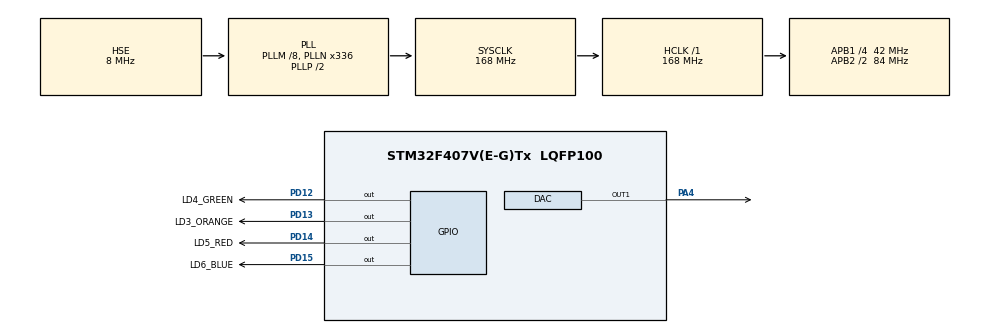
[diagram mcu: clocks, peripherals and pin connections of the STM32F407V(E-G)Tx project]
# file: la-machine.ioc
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DAC.DAC_Trigger=DAC_TRIGGER_T6_TRGO
Dma.DAC1.0.Direction=DMA_MEMORY_TO_PERIPH
Dma.DAC1.0.FIFOMode=DMA_FIFOMODE_DISABLE
Dma.DAC1.0.Instance=DMA1_Stream5
Dma.DAC1.0.MemDataAlignment=DMA_MDATAALIGN_HALFWORD
Dma.DAC1.0.MemInc=DMA_MINC_ENABLE
Dma.DAC1.0.Mode=DMA_CIRCULAR
Dma.DAC1.0.PeriphDataAlignment=DMA_PDATAALIGN_HALFWORD
Dma.DAC1.0.PeriphInc=DMA_PINC_DISABLE
Dma.DAC1.0.Priority=DMA_PRIORITY_LOW
Dma.Request0=DAC1
Mcu.Family=STM32F4
Mcu.Name=STM32F407V(E-G)Tx
Mcu.Package=LQFP100
NVIC.DMA1_Stream5_IRQn=true\:0\:0\:false\:false\:true\:false\:true\:true
NVIC.PriorityGroup=NVIC_PRIORITYGROUP_4
PA4.Signal=COMP_DAC1_group
PD12.GPIO_Label=LD4_GREEN
PD12.Signal=GPIO_Output
PD13.GPIO_Label=LD3_ORANGE
PD13.Signal=GPIO_Output
PD14.GPIO_Label=LD5_RED
PD14.Signal=GPIO_Output
PD15.GPIO_Label=LD6_BLUE
PD15.Signal=GPIO_Output
PH0-OSC_IN.Mode=HSE-External-Oscillator
PH0-OSC_IN.Signal=RCC_OSC_IN
PH1-OSC_OUT.Mode=HSE-External-Oscillator
PH1-OSC_OUT.Signal=RCC_OSC_OUT
ProjectManager.HeapSize=0x200
ProjectManager.StackSize=0x400
ProjectManager.TargetToolchain=Makefile
RCC.48MHZClocksFreq_Value=84000000
RCC.AHBFreq_Value=168000000
RCC.APB1CLKDivider=RCC_HCLK_DIV4
RCC.APB1Freq_Value=42000000
RCC.APB1TimFreq_Value=84000000
RCC.APB2CLKDivider=RCC_HCLK_DIV2
RCC.APB2Freq_Value=84000000
RCC.APB2TimFreq_Value=168000000
RCC.CortexFreq_Value=168000000
RCC.HCLKFreq_Value=168000000
RCC.HSE_VALUE=8000000
RCC.HSI_VALUE=16000000
RCC.LSE_VALUE=32768
RCC.PLLM=8
RCC.PLLN=336
RCC.PLLSourceVirtual=RCC_PLLSOURCE_HSE
RCC.SYSCLKFreq_VALUE=168000000
RCC.SYSCLKSource=RCC_SYSCLKSOURCE_PLLCLK
RCC.VCOOutputFreq_Value=336000000
SH.COMP_DAC1_group.0=DAC_OUT1,DAC_OUT1
TIM6.Period=1749
TIM6.TIM_MasterOutputTrigger=TIM_TRGO_UPDATE
VP_TIM6_VS_ClockSourceINT.Mode=Enable_Timer
board=custom

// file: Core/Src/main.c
/* USER CODE BEGIN Header */
/**
 ******************************************************************************
 * @file           : main.c
 * @brief          : Main program body
 ******************************************************************************
 * @attention
 *
 * Copyright (c) 2026 STMicroelectronics.
 * All rights reserved.
 *
 * This software is licensed under terms that can be found in the LICENSE file
 * in the root directory of this software component.
 * If no LICENSE file comes with this software, it is provided AS-IS.
 *
 ******************************************************************************
 */
/* USER CODE END Header */
#include "main.h"

/* USER CODE BEGIN Includes */

#include <math.h>

/* USER CODE END Includes */

DAC_HandleTypeDef hdac;
DMA_HandleTypeDef hdma_dac1;

TIM_HandleTypeDef htim6;

/* USER CODE BEGIN PV */
#define WAVETABLE_SIZE 512
float k_sine_wt[WAVETABLE_SIZE];

/* USER CODE END PV */

void SystemClock_Config(void);
static void MX_GPIO_Init(void);
static void MX_DMA_Init(void);
static void MX_DAC_Init(void);
static void MX_TIM6_Init(void);

/* USER CODE BEGIN 0 */

static void init_wavetables(void)
{
    // i might codegen this later
    for (int i = 0; i < WAVETABLE_SIZE; i++) {
        const float phase = (2.0f * 3.14159265f * i) / WAVETABLE_SIZE;
        k_sine_wt[i] = sinf(phase);
    }
}

/* USER CODE END 0 */

int main(void)
{
    /* USER CODE BEGIN 1 */
    init_wavetables();

    /* USER CODE END 1 */

    /* MCU
     * Configuration--------------------------------------------------------*/

    /* Reset of all peripherals, Initializes the Flash interface and the
     * Systick. */
    HAL_Init();

    /* Configure the system clock */
    SystemClock_Config();

    /* Initialize all configured peripherals */
    MX_GPIO_Init();
    MX_DMA_Init();
    MX_DAC_Init();
    MX_TIM6_Init();

    /* Infinite loop */
    while (1) {

    }
}

void SystemClock_Config(void)
{
    RCC_OscInitTypeDef RCC_OscInitStruct = {0};
    RCC_ClkInitTypeDef RCC_ClkInitStruct = {0};

    /** Configure the main internal regulator output voltage
     */
    __HAL_RCC_PWR_CLK_ENABLE();
    __HAL_PWR_VOLTAGESCALING_CONFIG(PWR_REGULATOR_VOLTAGE_SCALE1);

    /** Initializes the RCC Oscillators according to the specified parameters
     * in the RCC_OscInitTypeDef structure.
     */
    RCC_OscInitStruct.OscillatorType = RCC_OSCILLATORTYPE_HSE;
    RCC_OscInitStruct.HSEState = RCC_HSE_ON;
    RCC_OscInitStruct.PLL.PLLState = RCC_PLL_ON;
    RCC_OscInitStruct.PLL.PLLSource = RCC_PLLSOURCE_HSE;
    RCC_OscInitStruct.PLL.PLLM = 8;
    RCC_OscInitStruct.PLL.PLLN = 336;
    RCC_OscInitStruct.PLL.PLLP = RCC_PLLP_DIV2;
    RCC_OscInitStruct.PLL.PLLQ = 4;
    if (HAL_RCC_OscConfig(&RCC_OscInitStruct) != HAL_OK) {
        Error_Handler();
    }

    /** Initializes the CPU, AHB and APB buses clocks
     */
    RCC_ClkInitStruct.ClockType = RCC_CLOCKTYPE_HCLK | RCC_CLOCKTYPE_SYSCLK |
                                  RCC_CLOCKTYPE_PCLK1 | RCC_CLOCKTYPE_PCLK2;
    RCC_ClkInitStruct.SYSCLKSource = RCC_SYSCLKSOURCE_PLLCLK;
    RCC_ClkInitStruct.AHBCLKDivider = RCC_SYSCLK_DIV1;
    RCC_ClkInitStruct.APB1CLKDivider = RCC_HCLK_DIV4;
    RCC_ClkInitStruct.APB2CLKDivider = RCC_HCLK_DIV2;

    if (HAL_RCC_ClockConfig(&RCC_ClkInitStruct, FLASH_LATENCY_5) != HAL_OK) {
        Error_Handler();
    }
}

static void MX_DAC_Init(void)
{

    DAC_ChannelConfTypeDef sConfig = {0};

    /** DAC Initialization
     */
    hdac.Instance = DAC;
    if (HAL_DAC_Init(&hdac) != HAL_OK) {
        Error_Handler();
    }

    /** DAC channel OUT1 config
     */
    sConfig.DAC_Trigger = DAC_TRIGGER_T6_TRGO;
    sConfig.DAC_OutputBuffer = DAC_OUTPUTBUFFER_ENABLE;
    if (HAL_DAC_ConfigChannel(&hdac, &sConfig, DAC_CHANNEL_1) != HAL_OK) {
        Error_Handler();
    }
}

static void MX_TIM6_Init(void)
{

    TIM_MasterConfigTypeDef sMasterConfig = {0};

    htim6.Instance = TIM6;
    htim6.Init.Prescaler = 0;
    htim6.Init.CounterMode = TIM_COUNTERMODE_UP;
    htim6.Init.Period = 1749;
    htim6.Init.AutoReloadPreload = TIM_AUTORELOAD_PRELOAD_DISABLE;
    if (HAL_TIM_Base_Init(&htim6) != HAL_OK) {
        Error_Handler();
    }
    sMasterConfig.MasterOutputTrigger = TIM_TRGO_UPDATE;
    sMasterConfig.MasterSlaveMode = TIM_MASTERSLAVEMODE_DISABLE;
    if (HAL_TIMEx_MasterConfigSynchronization(&htim6, &sMasterConfig) !=
        HAL_OK) {
        Error_Handler();
    }
}

static void MX_DMA_Init(void)
{
    /* DMA controller clock enable */
    __HAL_RCC_DMA1_CLK_ENABLE();

    /* DMA interrupt init */
    /* DMA1_Stream5_IRQn interrupt configuration */
    HAL_NVIC_SetPriority(DMA1_Stream5_IRQn, 0, 0);
    HAL_NVIC_EnableIRQ(DMA1_Stream5_IRQn);
}

static void MX_GPIO_Init(void)
{
    GPIO_InitTypeDef GPIO_InitStruct = {0};

    /* GPIO Ports Clock Enable */
    __HAL_RCC_GPIOH_CLK_ENABLE();
    __HAL_RCC_GPIOA_CLK_ENABLE();
    __HAL_RCC_GPIOD_CLK_ENABLE();

    /*Configure GPIO pin Output Level */
    HAL_GPIO_WritePin(
        GPIOD, LD4_GREEN_Pin | LD3_ORANGE_Pin | LD5_RED_Pin | LD6_BLUE_Pin,
        GPIO_PIN_RESET);

    /*Configure GPIO pins : LD4_GREEN_Pin LD3_ORANGE_Pin LD5_RED_Pin
     * LD6_BLUE_Pin */
    GPIO_InitStruct.Pin =
        LD4_GREEN_Pin | LD3_ORANGE_Pin | LD5_RED_Pin | LD6_BLUE_Pin;
    GPIO_InitStruct.Mode = GPIO_MODE_OUTPUT_PP;
    GPIO_InitStruct.Pull = GPIO_NOPULL;
    GPIO_InitStruct.Speed = GPIO_SPEED_FREQ_LOW;
    HAL_GPIO_Init(GPIOD, &GPIO_InitStruct);

}

void Error_Handler(void)
{
    /* USER CODE BEGIN Error_Handler_Debug */
    /* User can add his own implementation to report the HAL error return state
     */
    __disable_irq();
    while (1) {
    }
    /* USER CODE END Error_Handler_Debug */
}
#ifdef USE_FULL_ASSERT
/**
 * @brief  Reports the name of the source file and the source line number
 *         where the assert_param error has occurred.
 * @param  file: pointer to the source file name
 * @param  line: assert_param error line source number
 * @retval None
 */
void assert_failed(uint8_t* file, uint32_t line)
{
    /* USER CODE BEGIN 6 */
    /* User can add his own implementation to report the file name and line
       number, ex: printf("Wrong parameters value: file %s on line %d\r\n",
       file, line) */
    /* USER CODE END 6 */
}
#endif /* USE_FULL_ASSERT */
